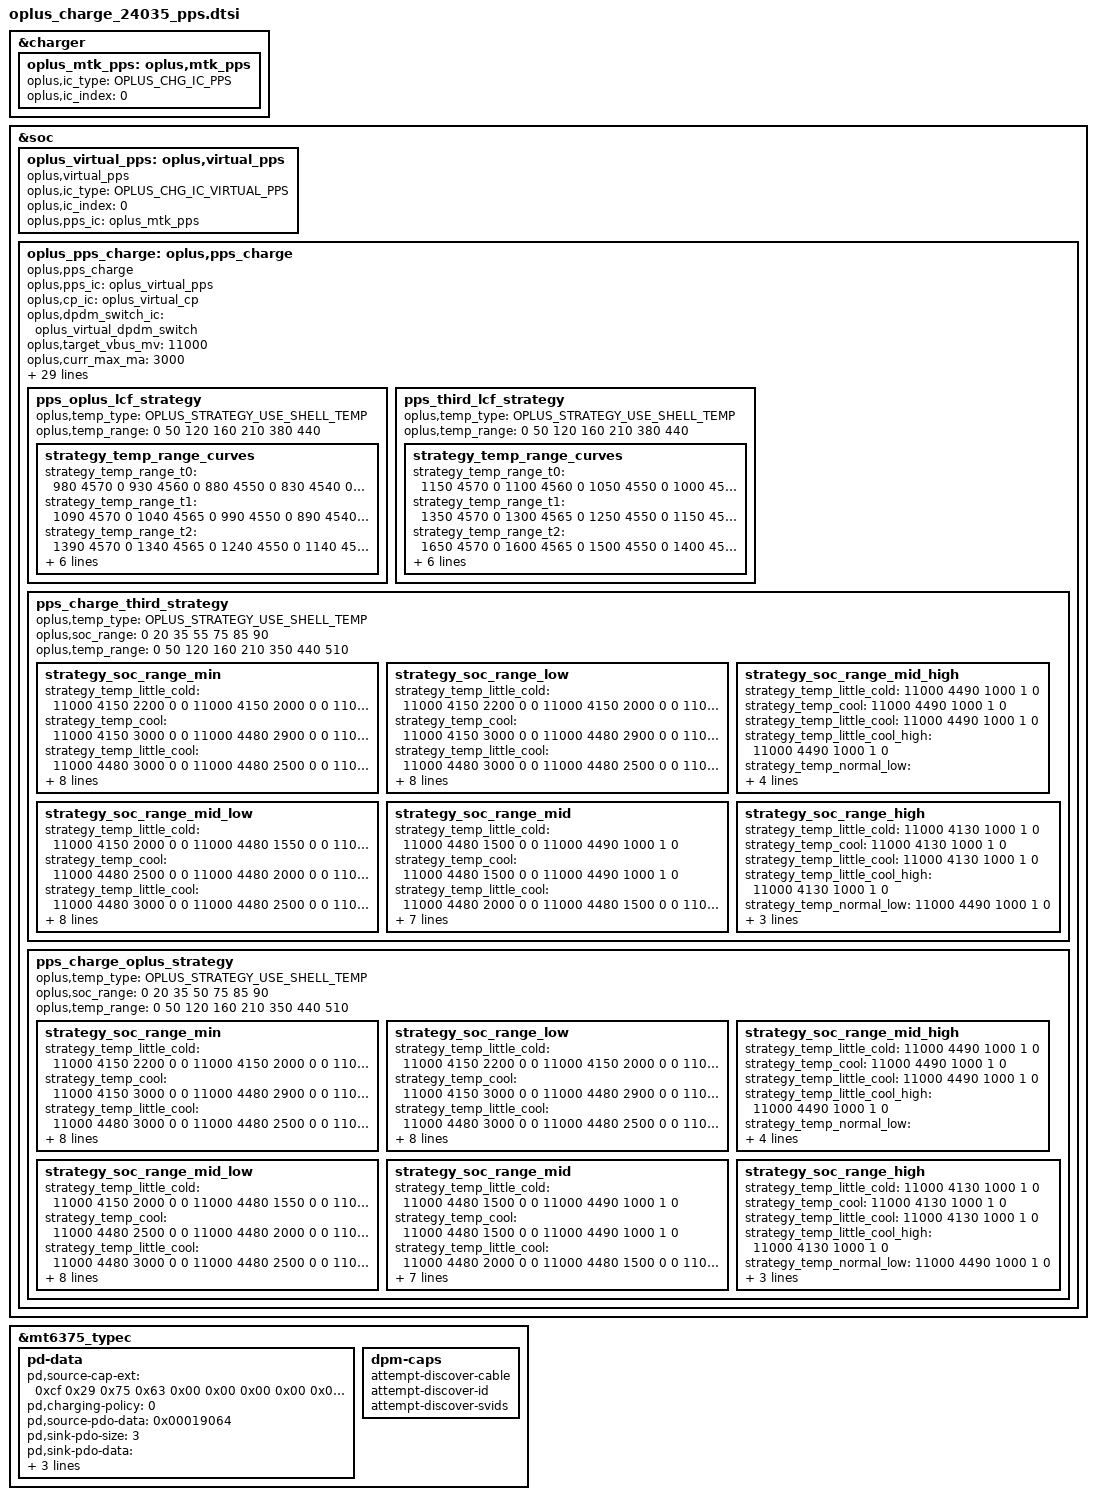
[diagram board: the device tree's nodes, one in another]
//ifdef OPLUS_FEATURE_CHG_BASIC
&charger {
	oplus_mtk_pps: oplus,mtk_pps {
		oplus,ic_type = <OPLUS_CHG_IC_PPS>;
		oplus,ic_index = <0>;
	};
};
&soc {
	oplus_virtual_pps: oplus,virtual_pps {
		compatible = "oplus,virtual_pps";

		oplus,ic_type = <OPLUS_CHG_IC_VIRTUAL_PPS>;
		oplus,ic_index = <0>;
		oplus,pps_ic = <&oplus_mtk_pps>;
	};
	oplus_pps_charge: oplus,pps_charge {
		compatible = "oplus,pps_charge";
		oplus,pps_ic = <&oplus_virtual_pps>;
		oplus,cp_ic = <&oplus_virtual_cp>;
		oplus,dpdm_switch_ic = <&oplus_virtual_dpdm_switch>;

		oplus,target_vbus_mv = <11000>;
		oplus,curr_max_ma = <3000>;

		oplus,pps_warm_allow_vol = <4000>;
		oplus,pps_warm_allow_soc = <55>;
		oplus,pps_strategy_normal_current = <3000>;
		oplus,pps_over_high_or_low_current = <3000>;
		oplus,pps_timeout_third = <17562>;
		oplus,pps_timeout_oplus = <17562>;
		oplus,pps_ibat_over_third = <7400>;
		oplus,pps_ibat_over_oplus = <7400>;
		oplus,pps_full_cool_sw_vbat = <4490>;
		oplus,pps_full_normal_sw_vbat = <4490>;
		oplus,pps_full_normal_hw_vbat = <4500>;
		oplus,pps_full_ffc_vbat = <4510>;
		oplus,pps_full_warm_vbat = <4130>;
		oplus,pps_full_cool_sw_vbat_third = <4490>;
		oplus,pps_full_normal_sw_vbat_third= <4490>;
		oplus,pps_full_normal_hw_vbat_third = <4500>;
		oplus,pps_current_change_timeout = <100>;
		oplus,curve_strategy_name = "pps_ufcs_curve_v2";
		oplus,pps_strategy_batt_high_temp = <410 420 430 400 410 420>;
		oplus,pps_strategy_high_current = <3000 2000 2000 3000 3000 3000>;
		oplus,pps_little_cool_high_temp = <210>;
		oplus,pps_charge_strategy_soc = <0 20 35 55 75 85 90>;
		oplus,pps_charge_strategy_temp = <0 50 120 160 350 440 510>;

		oplus,plc_strategy-data = <&pps_simple_strategy>;
		oplus,plc_strategy-names = "default";

		pps_oplus_lcf_strategy {
			oplus,temp_type = <OPLUS_STRATEGY_USE_SHELL_TEMP>;
			oplus,temp_range = <0 50 120 160 210 380 440>;

			strategy_temp_range_curves {
				strategy_temp_range_t0 =	<980 4570 0
								 930 4560 0
								 880 4550 0
								 830 4540 0
								 780 4530 1>;
				strategy_temp_range_t1 =	<1090 4570 0
								 1040 4565 0
								 990 4550 0
								 890 4540 0
								 790 4530 1>;
				strategy_temp_range_t2 =	<1390 4570 0
								 1340 4565 0
								 1240 4550 0
								 1140 4540 0
								 990 4530 1>;
				strategy_temp_range_t3 =	<1390 4570 0
								 1340 4565 0
								 1240 4550 0
								 1140 4540 0
								 990 4530 1>;
				strategy_temp_range_t4 =	<2250 4559 0
								 2100 4550 0
								 1900 4541 0
								 1700 4532 0
								 1500 4510 1>;
				strategy_temp_range_t5 =	<2850 4558 0
								 2650 4550 0
								 2100 4532 0
								 1550 4510 0
								 1000 4490 1>;
			};
		};

		pps_third_lcf_strategy {
			oplus,temp_type = <OPLUS_STRATEGY_USE_SHELL_TEMP>;
			oplus,temp_range = <0 50 120 160 210 380 440>;

			strategy_temp_range_curves {
				strategy_temp_range_t0 =	<1150 4570 0
								 1100 4560 0
								 1050 4550 0
								 1000 4540 0
								 950 4530 1>;
				strategy_temp_range_t1 =	<1350 4570 0
								 1300 4565 0
								 1250 4550 0
								 1150 4540 0
								 1050 4530 1>;
				strategy_temp_range_t2 =	<1650 4570 0
								 1600 4565 0
								 1500 4550 0
								 1400 4540 0
								 1250 4530 1>;
				strategy_temp_range_t3 =	<1650 4570 0
								 1600 4565 0
								 1500 4550 0
								 1400 4540 0
								 1250 4530 1>;
				strategy_temp_range_t4 =	<2250 4559 0
								 2100 4550 0
								 1900 4541 0
								 1700 4532 0
								 1500 4510 1>;
				strategy_temp_range_t5 =	<4600 4560 0
								 3700 4520 0
								 2800 4500 0
								 1900 4490 0
								 1000 4472 1>;
			};
		};

		pps_charge_third_strategy {
			oplus,temp_type = <OPLUS_STRATEGY_USE_SHELL_TEMP>;
			oplus,soc_range = <0 20 35 55 75 85 90>;
			oplus,temp_range = <0 50 120 160 210 350 440 510>;

			strategy_soc_range_min { /* 0-20 */
				strategy_temp_little_cold =	<11000 4150 2200 0 0 /* 0-5 */
								11000 4150 2000 0 0
								11000 4480 1550 0 0
								11000 4480 1500 0 0
								11000 4490 1000 1 0>;
				strategy_temp_cool =		<11000 4150 3000 0 0 /* 5-12 */
								11000 4480 2900 0 0
								11000 4480 2500 0 0
								11000 4480 2000 0 0
								11000 4480 1550 0 0
								11000 4480 1500 0 0
								11000 4490 1000 1 0>;
				strategy_temp_little_cool =	<11000 4480 3000 0 0 /* 12-16 */
								11000 4480 2500 0 0
								11000 4480 2000 0 0
								11000 4480 1500 0 0
								11000 4490 1000 1 0>;
				strategy_temp_little_cool_high = <11000 4480 3000 0 0 /* 16-21 */
								11000 4480 2500 0 0
								11000 4480 2000 0 0
								11000 4480 1500 0 0
								11000 4490 1000 1 0>;
				strategy_temp_normal_low =	<11000 4480 3000 0 0 /* 21-35 */
								11000 4480 2500 0 0
								11000 4480 2000 0 0
								11000 4480 1500 0 0
								11000 4490 1000 1 0>;
				strategy_temp_normal_high =	<11000 4460 3000 0 0 /* 35-44 */
								11000 4460 2500 0 0
								11000 4460 2000 0 0
								11000 4460 1500 0 0
								11000 4470 1000 1 0>;
				strategy_temp_warm =		<11000 4120 1850 0 0 /* 44-51 */
								11000 4120 1500 0 0
								11000 4130 1000 1 0>;
			};
			strategy_soc_range_low { /* 21-35 */
				strategy_temp_little_cold =	<11000 4150 2200 0 0 /* 0-5 */
								11000 4150 2000 0 0
								11000 4480 1550 0 0
								11000 4480 1500 0 0
								11000 4490 1000 1 0>;
				strategy_temp_cool =		<11000 4150 3000 0 0 /* 5-12 */
								11000 4480 2900 0 0
								11000 4480 2500 0 0
								11000 4480 2000 0 0
								11000 4480 1550 0 0
								11000 4480 1500 0 0
								11000 4490 1000 1 0>;
				strategy_temp_little_cool =	<11000 4480 3000 0 0 /* 12-16 */
								11000 4480 2500 0 0
								11000 4480 2000 0 0
								11000 4480 1500 0 0
								11000 4490 1000 1 0>;
				strategy_temp_little_cool_high = <11000 4480 3000 0 0 /* 16-21 */
								11000 4480 2500 0 0
								11000 4480 2000 0 0
								11000 4480 1500 0 0
								11000 4490 1000 1 0>;
				strategy_temp_normal_low =	<11000 4480 3000 0 0 /* 21-35 */
								11000 4480 2500 0 0
								11000 4480 2000 0 0
								11000 4480 1500 0 0
								11000 4490 1000 1 0>;
				strategy_temp_normal_high =	<11000 4460 3000 0 0 /* 35-44 */
								11000 4460 2500 0 0
								11000 4460 2000 0 0
								11000 4460 1500 0 0
								11000 4470 1000 1 0>;
				strategy_temp_warm =		<11000 4120 1850 0 0 /* 44-51 */
								11000 4120 1500 0 0
								11000 4130 1000 1 0>;
			};
			strategy_soc_range_mid_low { /* 36-55 */
				strategy_temp_little_cold =	<11000 4150 2000 0 0 /* 0-5 */
								11000 4480 1550 0 0
								11000 4480 1500 0 0
								11000 4490 1000 1 0>;
				strategy_temp_cool =		<11000 4480 2500 0 0 /* 5-12 */
								11000 4480 2000 0 0
								11000 4480 1550 0 0
								11000 4480 1500 0 0
								11000 4490 1000 1 0>;
				strategy_temp_little_cool =	<11000 4480 3000 0 0 /* 12-16 */
								11000 4480 2500 0 0
								11000 4480 2000 0 0
								11000 4480 1500 0 0
								11000 4490 1000 1 0>;
				strategy_temp_little_cool_high = <11000 4480 3000 0 0 /* 16-21 */
								11000 4480 2500 0 0
								11000 4480 2000 0 0
								11000 4480 1500 0 0
								11000 4490 1000 1 0>;
				strategy_temp_normal_low =	<11000 4480 3000 0 0 /* 21-35 */
								11000 4480 2500 0 0
								11000 4480 2000 0 0
								11000 4480 1500 0 0
								11000 4490 1000 1 0>;
				strategy_temp_normal_high =	<11000 4460 3000 0 0 /* 35-44 */
								11000 4460 2500 0 0
								11000 4460 2000 0 0
								11000 4460 1500 0 0
								11000 4470 1000 1 0>;
				strategy_temp_warm =		<11000 4120 1850 0 0 /* 44-51 */
								11000 4120 1500 0 0
								11000 4130 1000 1 0>;
			};
			strategy_soc_range_mid { /* 56-75 */
				strategy_temp_little_cold =	<11000 4480 1500 0 0 /* 0-5 */
								11000 4490 1000 1 0>;
				strategy_temp_cool =		<11000 4480 1500 0 0 /* 5-12 */
								11000 4490 1000 1 0>;
				strategy_temp_little_cool =	<11000 4480 2000 0 0 /* 12-16 */
								11000 4480 1500 0 0
								11000 4490 1000 1 0>;
				strategy_temp_little_cool_high = <11000 4480 2000 0 0 /* 16-21 */
								11000 4480 1500 0 0
								11000 4490 1000 1 0>;
				strategy_temp_normal_low =	<11000 4480 2000 0 0 /* 21-35 */
								11000 4480 1500 0 0
								11000 4490 1000 1 0>;
				strategy_temp_normal_high =	<11000 4460 2500 0 0 /* 35-44 */
								11000 4460 2000 0 0
								11000 4460 1500 0 0
								11000 4470 1000 1 0>;
				strategy_temp_warm =		<11000 4130 1000 1 0>; /* 44-51 */
			};
			strategy_soc_range_mid_high { /* 76-85 */
				strategy_temp_little_cold =	<11000 4490 1000 1 0>; /* 0-5 */
				strategy_temp_cool =		<11000 4490 1000 1 0>; /* 5-12 */
				strategy_temp_little_cool =	<11000 4490 1000 1 0>; /* 12-16 */
				strategy_temp_little_cool_high = <11000 4490 1000 1 0>; /* 16-21 */
				strategy_temp_normal_low =	<11000 4480 1500 0 0 /* 21-35 */
								11000 4490 1000 1 0>;
				strategy_temp_normal_high =	<11000 4460 1500 0 0 /* 35-44 */
								11000 4470 1000 1 0>;
				strategy_temp_warm =		<11000 4130 1000 1 0>; /* 44-51 */
			};
			strategy_soc_range_high { /* 86-90 */
				strategy_temp_little_cold =	<11000 4130 1000 1 0>; /* 0-5 */
				strategy_temp_cool =		<11000 4130 1000 1 0>; /* 5-12 */
				strategy_temp_little_cool =	<11000 4130 1000 1 0>; /* 12-16 */
				strategy_temp_little_cool_high = <11000 4130 1000 1 0>; /* 16-21 */
				strategy_temp_normal_low =	<11000 4490 1000 1 0>; /* 21-35 */
				strategy_temp_normal_high =	<11000 4460 1500 0 0 /* 35-44 */
								11000 4470 1000 1 0>;
				strategy_temp_warm =		<11000 4130 1000 1 0>; /* 44-51 */
			};
		};

		pps_charge_oplus_strategy {
			oplus,temp_type = <OPLUS_STRATEGY_USE_SHELL_TEMP>;
			oplus,soc_range = <0 20 35 50 75 85 90>;
			oplus,temp_range = <0 50 120 160 210 350 440 510>;

			strategy_soc_range_min { /* 0-20 */
				strategy_temp_little_cold =	<11000 4150 2200 0 0 /* 0-5 */
								11000 4150 2000 0 0
								11000 4480 1550 0 0
								11000 4480 1500 0 0
								11000 4490 1000 1 0>;
				strategy_temp_cool =		<11000 4150 3000 0 0 /* 5-12 */
								11000 4480 2900 0 0
								11000 4480 2500 0 0
								11000 4480 2000 0 0
								11000 4480 1550 0 0
								11000 4480 1500 0 0
								11000 4490 1000 1 0>;
				strategy_temp_little_cool =	<11000 4480 3000 0 0 /* 12-16 */
								11000 4480 2500 0 0
								11000 4480 2000 0 0
								11000 4480 1500 0 0
								11000 4490 1000 1 0>;
				strategy_temp_little_cool_high = <11000 4480 3000 0 0 /* 16-21 */
								11000 4480 2500 0 0
								11000 4480 2000 0 0
								11000 4480 1500 0 0
								11000 4490 1000 1 0>;
				strategy_temp_normal_low =	<11000 4480 3000 0 0 /* 21-35 */
								11000 4480 2500 0 0
								11000 4480 2000 0 0
								11000 4480 1500 0 0
								11000 4490 1000 1 0>;
				strategy_temp_normal_high =	<11000 4460 3000 0 0 /* 35-44 */
								11000 4460 2500 0 0
								11000 4460 2000 0 0
								11000 4460 1500 0 0
								11000 4470 1000 1 0>;
				strategy_temp_warm =		<11000 4120 1850 0 0 /* 44-51 */
								11000 4120 1500 0 0
								11000 4130 1000 1 0>;
			};
			strategy_soc_range_low { /* 21-35 */
				strategy_temp_little_cold =	<11000 4150 2200 0 0 /* 0-5 */
								11000 4150 2000 0 0
								11000 4480 1550 0 0
								11000 4480 1500 0 0
								11000 4490 1000 1 0>;
				strategy_temp_cool =		<11000 4150 3000 0 0 /* 5-12 */
								11000 4480 2900 0 0
								11000 4480 2500 0 0
								11000 4480 2000 0 0
								11000 4480 1550 0 0
								11000 4480 1500 0 0
								11000 4490 1000 1 0>;
				strategy_temp_little_cool =	<11000 4480 3000 0 0 /* 12-16 */
								11000 4480 2500 0 0
								11000 4480 2000 0 0
								11000 4480 1500 0 0
								11000 4490 1000 1 0>;
				strategy_temp_little_cool_high = <11000 4480 3000 0 0 /* 16-21 */
								11000 4480 2500 0 0
								11000 4480 2000 0 0
								11000 4480 1500 0 0
								11000 4490 1000 1 0>;
				strategy_temp_normal_low =	<11000 4480 3000 0 0 /* 21-35 */
								11000 4480 2500 0 0
								11000 4480 2000 0 0
								11000 4480 1500 0 0
								11000 4490 1000 1 0>;
				strategy_temp_normal_high =	<11000 4460 3000 0 0 /* 35-44 */
								11000 4460 2500 0 0
								11000 4460 2000 0 0
								11000 4460 1500 0 0
								11000 4470 1000 1 0>;
				strategy_temp_warm =		<11000 4120 1850 0 0 /* 44-51 */
								11000 4120 1500 0 0
								11000 4130 1000 1 0>;
			};
			strategy_soc_range_mid_low { /* 36-55 */
				strategy_temp_little_cold =	<11000 4150 2000 0 0 /* 0-5 */
								11000 4480 1550 0 0
								11000 4480 1500 0 0
								11000 4490 1000 1 0>;
				strategy_temp_cool =		<11000 4480 2500 0 0 /* 5-12 */
								11000 4480 2000 0 0
								11000 4480 1550 0 0
								11000 4480 1500 0 0
								11000 4490 1000 1 0>;
				strategy_temp_little_cool =	<11000 4480 3000 0 0 /* 12-16 */
								11000 4480 2500 0 0
								11000 4480 2000 0 0
								11000 4480 1500 0 0
								11000 4490 1000 1 0>;
				strategy_temp_little_cool_high = <11000 4480 3000 0 0 /* 16-21 */
								11000 4480 2500 0 0
								11000 4480 2000 0 0
								11000 4480 1500 0 0
								11000 4490 1000 1 0>;
				strategy_temp_normal_low =	<11000 4480 3000 0 0 /* 21-35 */
								11000 4480 2500 0 0
								11000 4480 2000 0 0
								11000 4480 1500 0 0
								11000 4490 1000 1 0>;
				strategy_temp_normal_high =	<11000 4460 3000 0 0 /* 35-44 */
								11000 4460 2500 0 0
								11000 4460 2000 0 0
								11000 4460 1500 0 0
								11000 4470 1000 1 0>;
				strategy_temp_warm =		<11000 4120 1850 0 0 /* 44-51 */
								11000 4120 1500 0 0
								11000 4130 1000 1 0>;
			};
			strategy_soc_range_mid { /* 56-75 */
				strategy_temp_little_cold =	<11000 4480 1500 0 0 /* 0-5 */
								11000 4490 1000 1 0>;
				strategy_temp_cool =		<11000 4480 1500 0 0 /* 5-12 */
								11000 4490 1000 1 0>;
				strategy_temp_little_cool =	<11000 4480 2000 0 0 /* 12-16 */
								11000 4480 1500 0 0
								11000 4490 1000 1 0>;
				strategy_temp_little_cool_high = <11000 4480 2000 0 0 /* 16-21 */
								11000 4480 1500 0 0
								11000 4490 1000 1 0>;
				strategy_temp_normal_low =	<11000 4480 2000 0 0 /* 21-35 */
								11000 4480 1500 0 0
								11000 4490 1000 1 0>;
				strategy_temp_normal_high =	<11000 4460 2500 0 0 /* 35-44 */
								11000 4460 2000 0 0
								11000 4460 1500 0 0
								11000 4470 1000 1 0>;
				strategy_temp_warm =		<11000 4130 1000 1 0>; /* 44-51 */
			};
			strategy_soc_range_mid_high { /* 76-85 */
				strategy_temp_little_cold =	<11000 4490 1000 1 0>; /* 0-5 */
				strategy_temp_cool =		<11000 4490 1000 1 0>; /* 5-12 */
				strategy_temp_little_cool =	<11000 4490 1000 1 0>; /* 12-16 */
				strategy_temp_little_cool_high = <11000 4490 1000 1 0>; /* 16-21 */
				strategy_temp_normal_low =	<11000 4480 1500 0 0 /* 21-35 */
								11000 4490 1000 1 0>;
				strategy_temp_normal_high =	<11000 4460 1500 0 0 /* 35-44 */
								11000 4470 1000 1 0>;
				strategy_temp_warm =		<11000 4130 1000 1 0>; /* 44-51 */
			};
			strategy_soc_range_high { /* 86-90 */
				strategy_temp_little_cold =	<11000 4130 1000 1 0>; /* 0-5 */
				strategy_temp_cool =		<11000 4130 1000 1 0>; /* 5-12 */
				strategy_temp_little_cool =	<11000 4130 1000 1 0>; /* 12-16 */
				strategy_temp_little_cool_high = <11000 4130 1000 1 0>; /* 16-21 */
				strategy_temp_normal_low =	<11000 4490 1000 1 0>; /* 21-35 */
				strategy_temp_normal_high =	<11000 4460 1500 0 0 /* 35-44 */
								11000 4470 1000 1 0>;
				strategy_temp_warm =		<11000 4130 1000 1 0>; /* 44-51 */
			};
		};
	};
};

/* for pd common charger */
&mt6375_typec {
	pd-data {
			pd,source-cap-ext = /bits/ 8 <0xcf 0x29 0x75 0x63
							      0x00 0x00 0x00 0x00
							      0x00 0x00 0x00 0x00
							      0x00 0x00 0x00 0x00
							      0x00 0x00 0x00 0x00
							      0x00 0x00 0x01 0x05
							      0x00>;

			pd,charging-policy = <0>;

			pd,source-pdo-data = <0x00019064>;/* Fixed, 5000mV, 1000mA*/

			/*0x000190c8: Fixed, 5000mV, 2000mA*/
			/*0x0002d096: Fixed, 9000mV, 1500mA*/
			/*0xc0dc1e64: apdo, min 3000mV, max 11000mV, 5000mA*/
			pd,sink-pdo-size = <3>;
			pd,sink-pdo-data = <0x000190c8 0x0002d096 0xc0dc1e64>;

			/* No DP, host + device */
			pd,id-vdo-data = <0xd14029cf 0x0 0x63750000
						  0x61000000 0x0 0x41000000>;
	};

	dpm-caps {
			// attempt-enter-dp-mode;
			attempt-discover-cable;
			attempt-discover-id;
			attempt-discover-svids;
	};
};

//#endif OPLUS_FEATURE_CHG_BASIC

